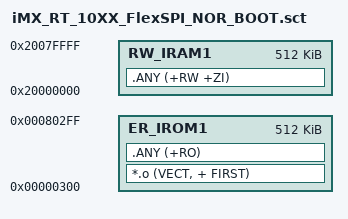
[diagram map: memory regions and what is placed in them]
;/* iMX_RT_10xx_FlexSPI_NOR.sct - for iMX RT 10xx running from FlexSPI NOR    */
;/* 256k..1M RAM                                                              */

LR_IROM1 0x00000300 0x00080000  {    ; load region size_region
  ER_IROM1 0x00000300 0x00080000  {  ; load address = execution address
   *.o (VECT, + FIRST)
   .ANY (+RO)
  }
  RW_IRAM1 0x20000000 0x00080000  {  ; RW data
   .ANY (+RW +ZI)
  }
}


